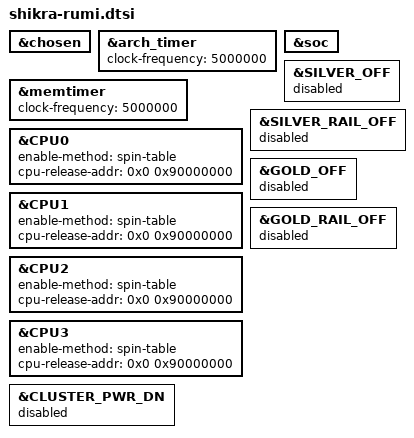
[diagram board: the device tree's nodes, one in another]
// SPDX-License-Identifier: BSD-3-Clause
/*
 * Copyright (c) Qualcomm Technologies, Inc. and/or its subsidiaries.
 */
&chosen {
};

&arch_timer {
	clock-frequency = <5000000>;
};

&memtimer {
	clock-frequency = <5000000>;
};

&CPU0 {
		enable-method = "spin-table"; /* TODO: Update to psci */
		cpu-release-addr = <0x0 0x90000000>;
};

&CPU1 {
		enable-method = "spin-table"; /* TODO: Update to psci */
		cpu-release-addr = <0x0 0x90000000>;
};

&CPU2 {
		enable-method = "spin-table"; /* TODO: Update to psci */
		cpu-release-addr = <0x0 0x90000000>;
};

&CPU3 {
		enable-method = "spin-table"; /* TODO: Update to psci */
		cpu-release-addr = <0x0 0x90000000>;
};

&soc {
};

&SILVER_OFF {
	status = "disabled";
};

&SILVER_RAIL_OFF {
	status = "disabled";
};

&GOLD_OFF {
	status = "disabled";
};

&GOLD_RAIL_OFF {
	status = "disabled";
};

&CLUSTER_PWR_DN {
	status = "disabled";
};
